# nrf9220_celldsp register map
Vendor: Nordic Semiconductor; Series: nRF92; File version: 1
Registers are 32-bit, read-write, reset 0x0 unless marked. A register's access mark holds for its fields unless they carry their own. Offsets are from the block's base; [hi:lo] are bit positions; {n}, {i} and the like mark numbered series; 'fields as' and 'values as' point back to an identical list.

## DECTSYNC — Pseudocoherent synchronization HW for DECT NR+ radio protocol
Base 0x4500F000
0x00 TASKS_STARTCROSCOR wo — Start cross correlation / detection metric calculation
  [0] TASKS_STARTCROSCOR
    1=Trigger task
0x04 TASKS_STARTMEMSET wo — Start memory clearing
  [0] TASKS_STARTMEMSET
    1=Trigger task
0x08 TASKS_STARTMAIN wo — Start top control Main function
  [0] TASKS_STARTMAIN
    1=Trigger task
0x0C TASKS_STARTSTOP wo — Start top control stop function
  [0] TASKS_STARTSTOP
    1=Trigger task
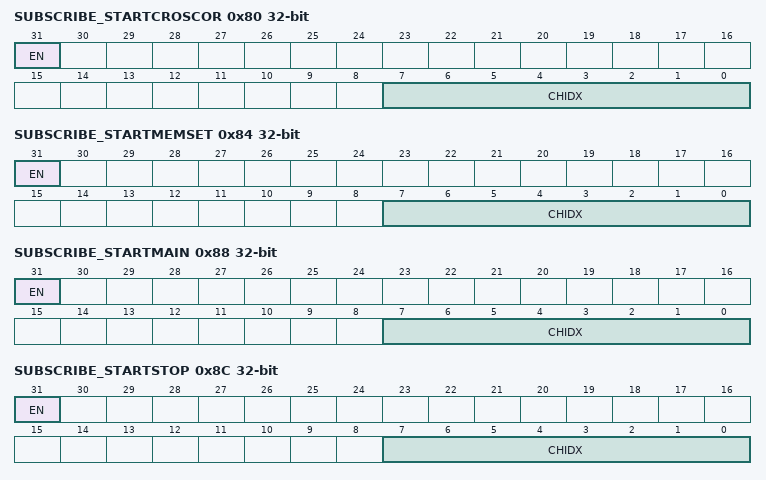
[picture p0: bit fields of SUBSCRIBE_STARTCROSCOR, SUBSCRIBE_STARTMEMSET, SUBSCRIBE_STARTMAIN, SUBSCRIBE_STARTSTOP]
0x80 SUBSCRIBE_STARTCROSCOR — Subscribe configuration for task STARTCROSCOR
  [31] EN
    0=Disabled (Disable subscription); 1=Enabled (Enable subscription)
  [7:0] CHIDX — DPPI channel that task STARTCROSCOR will subscribe to
0x84 SUBSCRIBE_STARTMEMSET — Subscribe configuration for task STARTMEMSET
  [31] EN
    values as SUBSCRIBE_STARTCROSCOR.EN
  [7:0] CHIDX — DPPI channel that task STARTMEMSET will subscribe to
0x88 SUBSCRIBE_STARTMAIN — Subscribe configuration for task STARTMAIN
  [31] EN
    values as SUBSCRIBE_STARTCROSCOR.EN
  [7:0] CHIDX — DPPI channel that task STARTMAIN will subscribe to
0x8C SUBSCRIBE_STARTSTOP — Subscribe configuration for task STARTSTOP
  [31] EN
    values as SUBSCRIBE_STARTCROSCOR.EN
  [7:0] CHIDX — DPPI channel that task STARTSTOP will subscribe to
0x100 EVENTS_BUSERROR — AXI bus error response received
  [0] EVENTS_BUSERROR
    0=NotGenerated (Event not generated); 1=Generated (Event generated)
0x104 EVENTS_CROSCORREADY — Cross correlation ready
  [0] EVENTS_CROSCORREADY
    values as EVENTS_BUSERROR.EVENTS_BUSERROR
0x108 EVENTS_MAINREADY — Main ready
  [0] EVENTS_MAINREADY
    values as EVENTS_BUSERROR.EVENTS_BUSERROR
0x10C EVENTS_MAINREADYNODETECTION — Main ready, no detection
  [0] EVENTS_MAINREADYNODETECTION
    values as EVENTS_BUSERROR.EVENTS_BUSERROR
0x110 EVENTS_MEMSETREADY — Memory set ready
  [0] EVENTS_MEMSETREADY
    values as EVENTS_BUSERROR.EVENTS_BUSERROR
0x114 EVENTS_ERROR — Calculation error event
  [0] EVENTS_ERROR
    values as EVENTS_BUSERROR.EVENTS_BUSERROR
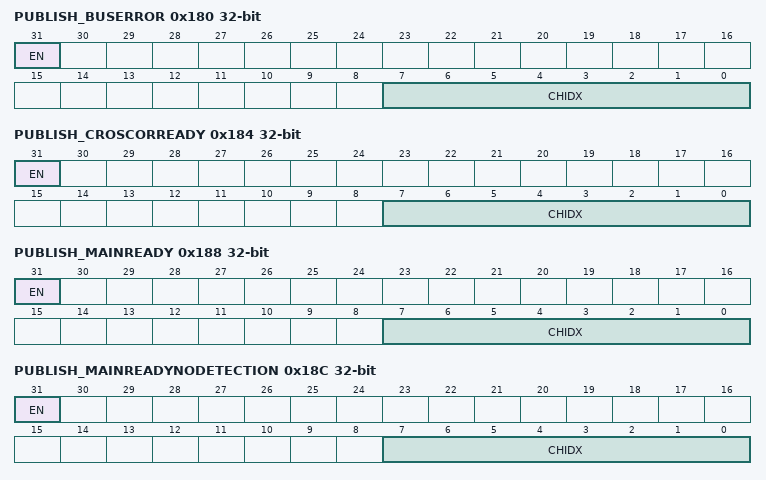
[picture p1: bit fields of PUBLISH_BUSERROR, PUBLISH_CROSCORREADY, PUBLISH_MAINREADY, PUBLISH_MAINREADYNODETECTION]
0x180 PUBLISH_BUSERROR — Publish configuration for event BUSERROR
  [31] EN
    0=Disabled (Disable publishing); 1=Enabled (Enable publishing)
  [7:0] CHIDX — DPPI channel that event BUSERROR will publish to
0x184 PUBLISH_CROSCORREADY — Publish configuration for event CROSCORREADY
  [31] EN
    values as PUBLISH_BUSERROR.EN
  [7:0] CHIDX — DPPI channel that event CROSCORREADY will publish to
0x188 PUBLISH_MAINREADY — Publish configuration for event MAINREADY
  [31] EN
    values as PUBLISH_BUSERROR.EN
  [7:0] CHIDX — DPPI channel that event MAINREADY will publish to
0x18C PUBLISH_MAINREADYNODETECTION — Publish configuration for event MAINREADYNODETECTION
  [31] EN
    values as PUBLISH_BUSERROR.EN
  [7:0] CHIDX — DPPI channel that event MAINREADYNODETECTION will publish to
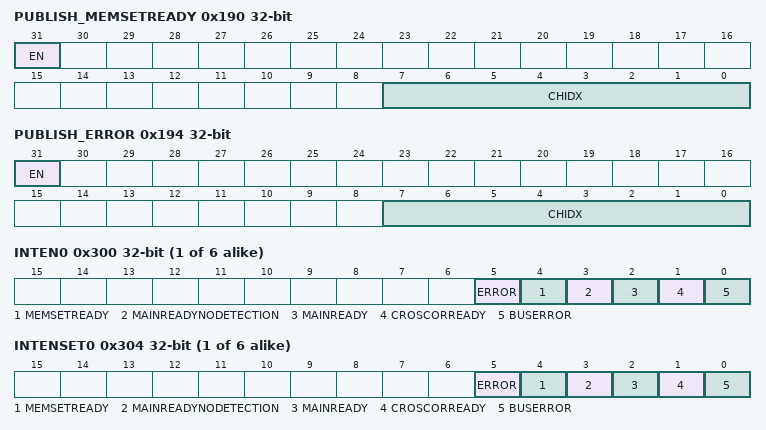
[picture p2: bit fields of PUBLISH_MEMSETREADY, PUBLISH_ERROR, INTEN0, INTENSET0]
0x190 PUBLISH_MEMSETREADY — Publish configuration for event MEMSETREADY
  [31] EN
    values as PUBLISH_BUSERROR.EN
  [7:0] CHIDX — DPPI channel that event MEMSETREADY will publish to
0x194 PUBLISH_ERROR — Publish configuration for event ERROR
  [31] EN
    values as PUBLISH_BUSERROR.EN
  [7:0] CHIDX — DPPI channel that event ERROR will publish to
{0x300+0x10*i} INTEN{i} (i=0..5) — Enable or disable interrupt
  [all] fields
    0=Disabled; 1=Enabled
  [5] ERROR — Enable or disable interrupt for event ERROR
  [4] MEMSETREADY — Enable or disable interrupt for event MEMSETREADY
  [3] MAINREADYNODETECTION — Enable or disable interrupt for event MAINREADYNODETECTION
  [2] MAINREADY — Enable or disable interrupt for event MAINREADY
  [1] CROSCORREADY — Enable or disable interrupt for event CROSCORREADY
  [0] BUSERROR — Enable or disable interrupt for event BUSERROR
{0x304+0x10*i} INTENSET{i} (i=0..5) — Enable interrupt
  [all] fields
    on read: 0=Disabled (Read: Disabled); 1=Enabled (Read: Enabled) | on write: 1=Set (Enable)
  [5] ERROR — Write '1' to enable interrupt for event ERROR
  [4] MEMSETREADY — Write '1' to enable interrupt for event MEMSETREADY
  [3] MAINREADYNODETECTION — Write '1' to enable interrupt for event MAINREADYNODETECTION
  [2] MAINREADY — Write '1' to enable interrupt for event MAINREADY
  [1] CROSCORREADY — Write '1' to enable interrupt for event CROSCORREADY
  [0] BUSERROR — Write '1' to enable interrupt for event BUSERROR
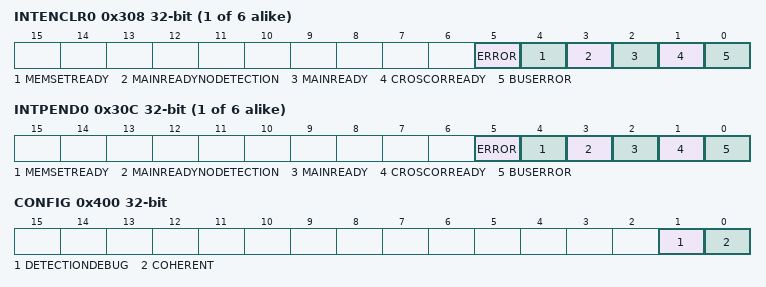
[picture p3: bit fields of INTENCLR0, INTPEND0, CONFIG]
{0x308+0x10*i} INTENCLR{i} (i=0..5) — Disable interrupt
  [all] fields
    on read: 0=Disabled (Read: Disabled); 1=Enabled (Read: Enabled) | on write: 1=Clear (Disable)
  [5] ERROR — Write '1' to disable interrupt for event ERROR
  [4] MEMSETREADY — Write '1' to disable interrupt for event MEMSETREADY
  [3] MAINREADYNODETECTION — Write '1' to disable interrupt for event MAINREADYNODETECTION
  [2] MAINREADY — Write '1' to disable interrupt for event MAINREADY
  [1] CROSCORREADY — Write '1' to disable interrupt for event CROSCORREADY
  [0] BUSERROR — Write '1' to disable interrupt for event BUSERROR
{0x30C+0x10*i} INTPEND{i} ro (i=0..5) — Pending interrupts
  [all] fields
    on read: 0=NotPending (Read: Not pending); 1=Pending (Read: Pending)
  [5] ERROR — Read pending status of interrupt for event ERROR
  [4] MEMSETREADY — Read pending status of interrupt for event MEMSETREADY
  [3] MAINREADYNODETECTION — Read pending status of interrupt for event MAINREADYNODETECTION
  [2] MAINREADY — Read pending status of interrupt for event MAINREADY
  [1] CROSCORREADY — Read pending status of interrupt for event CROSCORREADY
  [0] BUSERROR — Read pending status of interrupt for event BUSERROR
0x400 CONFIG — DECTSYNC configuration register
  [1] DETECTIONDEBUG — Detection debug mode
    1=Enable (Detection debug mode is enabled); 0=Disable (Detection debug mode is disabled)
  [0] COHERENT — Coherent sync mode
    1=Enable (Coherent sync mode is enabled); 0=Disable (Coherent sync mode is disabled)
0x404 Q — Single period length
  [7:0] Q
0x408 P — Number of periods
  [7:0] P
0x40C PMETRIC — Number of periods for detection metric
  [7:0] PMETRIC
0x410 OSF — Over sampling factor
  [7:0] OSF
0x414 STFADDR — Memory address for synchronization signal
0x418 COVER — Cover sequence
0x41C PWRSHIFT — Power shift value
  [7:0] PWRSHIFT
0x420 PSCOSHIFT — PSCO shift value
  [7:0] PSCOSHIFT
0x424 PSCOSCALE — PSCO scale value
  [15:0] PSCOSCALE
0x428 DETTHRSD — Detection threshold
  [15:0] DETTHRSD
0x42C DETLAG — Detection lag
  [15:0] DETLAG
0x430 RXBASEADDR — Rx circular buffer base address
  [31:0] RXBASEADDR — Rx circular buffer base address. 16 bytes aligned address.
0x434 RXWRAPADDR — Rx circular buffer wrap address
  [31:0] RXWRAPADDR — Rx circular buffer wrap address. 16 bytes aligned address.
0x438 RXSTRTADDR — Rx input start address
  [31:0] RXSTRTADDR — Rx input start address inside circular Rx buffer. 4 bytes (one complex sample) aligned address.
0x43C XCORRADDR — Cross correlation buffer start address
0x440 PSCOADDR — Pseudocoherent complex conjugate buffer start address
0x444 MEMCLRSTARTADDR — Memory clearing start address
0x448 MEMCLRSIZE — Size of memory area to be cleared
  [31:0] MEMCLRSIZE — Size (bytes) of memory area to be cleared
0x44C LASTPEAKIDX — Last Peak Index
0x450 LASTPEAKVALUE
  [15:0] LASTPEAKVALUE
0x454 DETECTIONDEBUGBASEADDR — Detection debug base address
0x458 SEARCHLIMIT
  [31:0] SEARCHLIMIT — Search limit. Maximum number of samples to search sync for. Set zero for unlimited search.
0x45C FRONTENDSAMPLECOUNT
  [31:0] FRONTENDSAMPLECOUNT — Initialization value for front end sample counter. Enables off-line processing.
